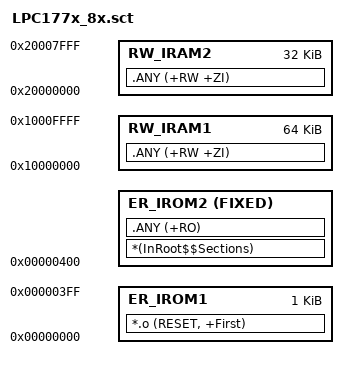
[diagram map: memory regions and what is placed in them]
; *************************************************************
; *** Scatter-Loading Description File generated by uVision ***
; *************************************************************

LR_IROM1 0x00000000 0x00080000  {    ; load region size_region
  ER_IROM1 0x00000000 0x00000400  {  ; load address = execution address
   *.o (RESET, +First)
  }

   ER_IROM2 0x00000400 FIXED   {  ; load address = execution address
   *(InRoot$$Sections)
   .ANY (+RO)
  }

   RW_IRAM1 0x10000000 0x00010000  {  ; RW data
        .ANY (+RW +ZI)
   }

    RW_IRAM2 0x20000000 0x00008000  {
        .ANY (+RW +ZI)
  }
}

